# tle984x register map
Vendor: Infineon; File version: 1.9.5
CPU: CM0 r2p1, little endian, no MPU, no FPU, 2 interrupt priority bits
Registers are 32-bit, read-write, reset 0x0 unless marked. A register's access mark holds for its fields unless they carry their own. Offsets are from the block's base; [hi:lo] are bit positions; 'fields as' and 'values as' point back to an identical list.

## TIMER2 — Timer2 registers
Base 0x48004000
Same registers: TIMER21 0x48005000
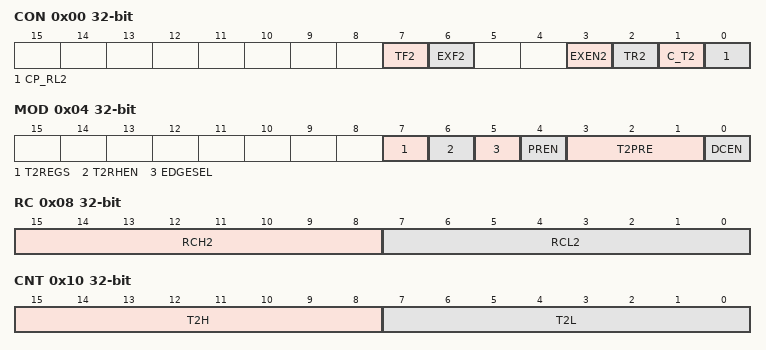
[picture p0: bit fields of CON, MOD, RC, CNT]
0x00 CON — Timer2 control register
  [7] TF2 ro — Timer2 overflow/underflow flag
  [6] EXF2 ro — Timer2 external flag
  [3] EXEN2 — Timer2 external enable control
    0=DISABLED (External events are disabled); 1=ENABLED (External events are enabled in capture/reload)
  [2] TR2 — Timer2 start/stop control
    0=STOP (Timer2); 1=START (Timer2)
  [1] C_T2 — Timer or counter select
    0=Timer (Function selected); 1=Count (Upon negative edge at pin T2)
  [0] CP_RL2 — Capture/reload select
    0=Reload (Upon overflow or upon negative/positive transition at pin T2EX (when EXEN2 = 1)); 1=Capture (Timer2 data register contents on the negative/positive transition at pin T2EX, provided EXEN2 = 1. The negative or positive transition at pin is selected by bit EDGESEL)
0x04 MOD — Timer2 mode register
  [7] T2REGS — Edge select for Timer2 external start
    0=FALLING (The falling edge at pin T2EX is selected); 1=RISING (The rising edge at Pin T2EX is selected)
  [6] T2RHEN — Timer2 external start enable
    0=DISABLED (Timer2 external start is disabled); 1=ENABLED (Timer2 external start is enabled)
  [5] EDGESEL — Edge select in capture mode/reload mode
    0=FALLING (The falling edge at Pin T2EX is selected); 1=RISING (The rising edge at Pin T2EX is selected)
  [4] PREN — Prescaler enable
    0=DISABLED (Prescaler is disabled and the 2 or 12 divider takes effect); 1=ENABLED (Prescaler is enabled (see T2PRE bit) and the 2 or 12 divider is bypassed)
  [3:1] T2PRE — Timer2 prescaler bit
    0=DIV1 (fT2=fSYS); 1=DIV2 (fT2=fSYS/2); 2=DIV4 (DfT2=fSYS/4); 3=DIV8 (fT2=fSYS/8); 4=DIV16 (fT2=fSYS/16); 5=DIV32 (fT2=fSYS/32); 6=DIV64 (fT2=fSYS/64); 7=DIV128 (fT2=fSYS/128)
  [0] DCEN — Up/down counter enable
    0=DISABLED (Up/down counter function is disabled); 1=ENABLED (Up/down counter function is enabled and controlled by pin T2EX (up = 1, down = 0))
0x08 RC — Timer2 reload/capture register
  [15:8] RCH2 — Reload/capture value
  [7:0] RCL2 — Reload/capture value
0x10 CNT — Timer2 count register
  [15:8] T2H — Timer2 value
  [7:0] T2L — Timer2 value
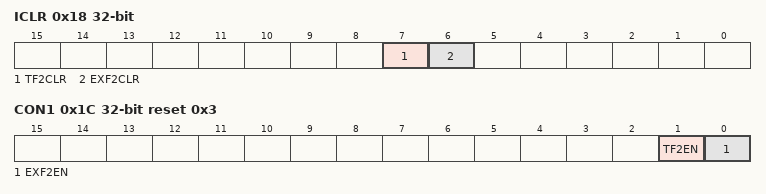
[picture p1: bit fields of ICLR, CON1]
0x18 ICLR — Timer2 interrupt clear register
  [7] TF2CLR wo — Overflow/underflow interrupt clear flag
    0=N_A (Overflow/underflow interrupt is not cleared); 1=Clear (Overflow/underflow interrupt)
  [6] EXF2CLR wo — External interrupt clear flag
    0=N_A (External interrupt is not cleared); 1=Clear (External interrupt)
0x1C CON1 reset 0x3 — Timer2 control 1 register
  [1] TF2EN — Overflow/underflow interrupt enable
    0=DISABLE (Overflow/underflow interrupt); 1=ENABLE (Overflow/underflow interrupt)
  [0] EXF2EN — External interrupt enable
    0=DISABLE (External interrupt); 1=ENABLE (External interrupt)

## TRX — Transceiver registers
Base 0x4801E000
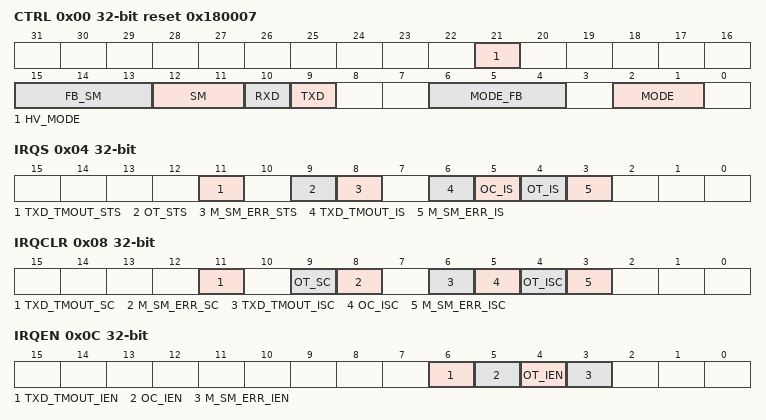
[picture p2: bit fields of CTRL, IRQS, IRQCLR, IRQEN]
0x00 CTRL reset 0x180007 (reset mask 0xFFFF00FF) — Transceiver control register
  [21] HV_MODE — Transceiver high-voltage I/O mode
    0=DISABLED (High-voltage mode entry disabled); 1=ENABLED (High-voltage mode entry enabled)
  [15:13] FB_SM ro — Feedback signal for slope mode setting [3:1]
    0=DISABLED (Transceiver module not enabled); 1=LOW (Low slope mode); 2=NORMAL (Normal slope mode); 3=FAST (Fast slope mode); 4=FLASH (Flash mode); 5=ERROR (Slope mode error); 6=ERROR (Slope mode error); 7=ERROR (Slope mode error)
  [12:11] SM — Transmitter slope mode control
    0=NORMAL (Normal slope mode); 1=FAST (Fast slope mode); 2=LOW (Low slope mode); 3=FLASH (Flash mode)
  [10] RXD ro — Reveiver output signal
  [9] TXD — Transmitter state (only used when HV_MODE is set)
    0=DOMINANT_STATE (Transmitter switched on); 1=RECESSIVE_STATE (Transmitter switched off)
  [6:4] MODE_FB ro — Transmitter feedback signals settings [2:1]
    0=ERROR (Mode error); 1=SLEEP (Transceiver Sleep mode); 2=ERROR (Mode error); 3=ERROR (Mode error); 4=ERROR (Mode error); 5=RECEIVE_ONLY (Transceiver Receive-Only mode); 6=ERROR (Mode error); 7=NORMAL (Transceiver Normal mode)
  [2:1] MODE — Transceiver power mode control
    0=SLEEP (Tranceiver module switched to Sleep mode); 1=RECEIVE_ONLY (Tranceiver module switched to Receive-Only mode); 3=NORMAL (Tranceiver module switched to Normal mode)
0x04 IRQS — Transceiver interrupt status register
  [11] TXD_TMOUT_STS — Transceiver TXD timeout status
    0=NO_TMOUT (No timeout occurred); 1=TMOUT (Timeout occurred)
  [9] OT_STS — Transceiver overtemperature status
    0=NO_OT (No overtemperature occurred); 1=OT (Overtemperature occurred)
  [8] M_SM_ERR_STS — Transceiver mode error - slope mode error status
    0=NO_ERROR (No mode error slope mode status occurred); 1=ERROR (Mode error status occurred)
  [6] TXD_TMOUT_IS — Transceiver TXD timeout interrupt status
    0=NO_TMOUT (No timeout occurred); 1=TMOUT (Timeout occurred)
  [5] OC_IS — Transceiver overcurrent interrupt status
    0=NO_OC (No overcurrent status occurred); 1=OC (Overcurrent status occurred)
  [4] OT_IS — Transceiver overtemperature interrupt status
    values as OT_STS
  [3] M_SM_ERR_IS — Transceiver mode error - slope mode error interrupt status
    values as M_SM_ERR_STS
0x08 IRQCLR — Transceiver interrupt status rclear register
  [11] TXD_TMOUT_SC wo — Transceiver TXD timeout status clear
    0=NO_CLR (No timeout cleared); 1=CLR (Timeout cleared)
  [9] OT_SC wo — Tranceiver overtemperature status clear
    0=NO_CLR (Overtemperature not cleared); 1=CLR (Overtemperature cleared)
  [8] M_SM_ERR_SC wo — Transceiver mode error - slope mode error status clear
    values as OT_SC
  [6] TXD_TMOUT_ISC wo — Transceiver TXD timeout interrupt status clear
    0=NO_CLR (No timeout cleared); 1=CLR (Timeout cleared)
  [5] OC_ISC wo — Tranceiver overcurrent interrupt status clear
    0=NO_CLR (Overcurrent status not cleared); 1=CLR (Overcurrent status cleared)
  [4] OT_ISC wo — Tranceiver overtemperature interrupt status / status clear
    values as OT_SC
  [3] M_SM_ERR_ISC wo — Transceiver mode error - slope mode error interrupt status clear
    values as OT_SC
0x0C IRQEN — Transceiver interrupt enable register
  [all] fields
    0=DISABLED; 1=ENABLED
  [6] TXD_TMOUT_IEN — Transceiver TxD-timeout interrupt
  [5] OC_IEN — Transceiver overcurrent interrupt
  [4] OT_IEN — Transceiver overtemperature interrupt
  [3] M_SM_ERR_IEN — Transceiver mode error - slope mode error interrupt

## UART1 — UART1 registers
Base 0x48020000
Same registers: UART2 0x48022000
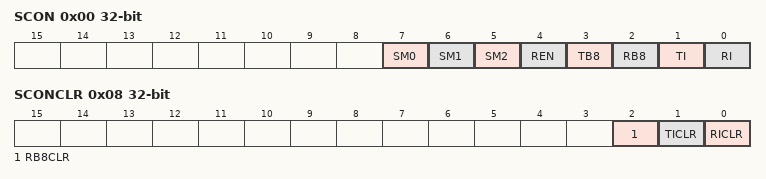
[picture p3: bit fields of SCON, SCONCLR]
0x00 SCON — Serial channel control register
  [7] SM0 — Serial port operating mode selection
  [6] SM1 — Serial port operating mode selection
  [5] SM2 — Enable serial port multiprocessor communication in modes 2 and 3
  [4] REN — Enable receiver of serial port
    0=DISABLE (Serial reception is disabled); 1=ENABLE (Serial reception is enabled)
  [3] TB8 — Serial port transmitter bit 9
  [2] RB8 — Serial port receiver bit 9
  [1] TI — Transmit interrupt flag
  [0] RI — Receive interrupt flag
0x04 SBUF — Serial data buffer register
  [7:0] VAL — Serial interface buffer register
0x08 SCONCLR — Serial channel control clear register
  [2] RB8CLR wo — SCON.RB8 clear flag
    0=Not_cleared (RB8 flag is not cleared); 1=Cleared (RB8 flag is cleared)
  [1] TICLR wo — SCON.TI clear flag
    0=Not_cleared (TI flag is not cleared); 1=Cleared (TI flag is cleared)
  [0] RICLR wo — SCON.RI clear flag
    0=Not_cleared (RI flag is not cleared); 1=Cleared (RI flag is cleared)
